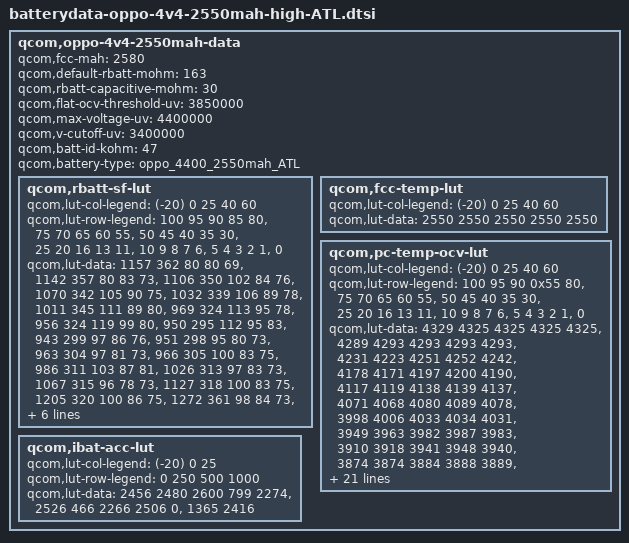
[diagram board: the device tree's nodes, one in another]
/* Copyright (c) 2020, The Linux Foundation. All rights reserved.
*  Copyright (c) 2020, the_shahnawaz_sheikh (sheikhshahnawaz41299).
*
* This program is free software; you can redistribute it and/or modify
* it under the terms of the GNU General Public License version 2 and
* only version 2 as published by the Free Software Foundation.
*
* This program is distributed in the hope that it will be useful,
* but WITHOUT ANY WARRANTY; without even the implied warranty of
* MERCHANTABILITY or FITNESS FOR A PARTICULAR PURPOSE.  See the
* GNU General Public License for more details.
*/

		qcom,oppo-4v4-2550mah-data {
			qcom,fcc-mah = <2580>;
			qcom,default-rbatt-mohm = <163>;
			qcom,rbatt-capacitive-mohm = <30>;
			qcom,flat-ocv-threshold-uv = <3850000>;
			qcom,max-voltage-uv = <4400000>;
			qcom,v-cutoff-uv = <3400000>;
			qcom,batt-id-kohm = <47>;
			qcom,battery-type = "oppo_4400_2550mah_ATL";

			qcom,rbatt-sf-lut {
				qcom,lut-col-legend = <(-20) 0 25 40 60>;
				qcom,lut-row-legend = <100 95 90 85 80>,
				                   <75 70 65 60 55>,
								   <50 45 40 35 30>,
								   <25 20 16 13 11>,
								   <10 9 8 7 6>,
								   <5 4 3 2 1>,
								   <0>;
				qcom,lut-data = <1157 362 80 80 69>,
				                 <1142 357 80 83 73>,
								 <1106 350 102 84 76>,
								 <1070 342 105 90 75>,
								 <1032 339 106 89 78>,
								 <1011 345 111 89 80>,
								 <969 324 113 95 78>,
								 <956 324 119 99 80>,
								 <950 295 112 95 83>,
								 <943 299 97 86 76>,
								 <951 298 95 80 73>,
								 <963 304 97 81 73>,
								 <966 305 100 83 75>,
								 <986 311 103 87 81>,
								 <1026 313 97 83 73>,
								 <1067 315 96 78 73>,
								 <1127 318 100 83 75>,
								 <1205 320 100 86 75>,
								 <1272 361 98 84 73>,
								 <1312 372 99 83 78>,
								 <1330 381 101 87 76>,
								 <1376 383 104 86 75>,
								 <1401 389 108 87 78>,
								 <1428 393 113 92 76>,
								 <1456 407 110 89 78>,
								 <1529 421 109 89 75>,
								 <1566 431 114 90 78>,
								 <1613 448 122 96 83>,
								 <1671 499 129 104 90>,
								 <1651 551 806 170 107>,
								 <4587 805 917 229 754>;
			};

			qcom,fcc-temp-lut {
				qcom,lut-col-legend = <(-20) 0 25 40 60>;
				qcom,lut-data = <2550 2550 2550 2550 2550>;
			};

			qcom,pc-temp-ocv-lut {
				qcom,lut-col-legend = <(-20) 0 25 40 60>;
				qcom,lut-row-legend = <100 95 90 0x55 80>,
				                       <75 70 65 60 55>,
									   <50 45 40 35 30>,
									   <25 20 16 13 11>,
									   <10 9 8 7 6>,
									   <5 4 3 2 1>,
									   <0>;
				qcom,lut-data = <4329 4325 4325 4325 4325>,
				                 <4289 4293 4293 4293 4293>,
								 <4231 4223 4251 4252 4242>,
								 <4178 4171 4197 4200 4190>,
								 <4117 4119 4138 4139 4137>,
								 <4071 4068 4080 4089 4078>,
								 <3998 4006 4033 4034 4031>,
								 <3949 3963 3982 3987 3983>,
								 <3910 3918 3941 3948 3940>,
								 <3874 3874 3884 3888 3889>,
								 <3846 3847 3856 3860 3855>,
								 <3824 3821 3829 3833 3832>,
								 <3805 3806 3813 3813 3809>,
								 <3792 3790 3796 3797 3795>,
								 <3783 3774 3779 3781 3778>,
								 <3773 3759 3762 3754 3744>,
								 <3759 3741 3743 3739 3725>,
								 <3743 3721 3722 3719 3705>,
								 <3727 3702 3702 3699 3687>,
								 <3718 3700 3697 3689 3678>,
								 <3713 3698 3694 3689 3679>,
								 <3707 3697 3693 3689 3677>,
								 <3703 3696 3694 3687 3675>,
								 <3700 3691 3689 3684 3672>,
								 <3697 3689 3685 3681 3668>,
								 <3688 3678 3670 3670 3636>,
								 <3682 3656 3605 3612 3604>,
								 <3673 3621 3560 3572 3566>,
								 <3661 3524 3506 3524 3520>,
								 <3611 3453 3326 3372 3382>,
								 <3000 3000 3000 3000 3000>;
			};

			qcom,ibat-acc-lut {
				qcom,lut-col-legend = <(-20) 0 25>;
				qcom,lut-row-legend = <0 250 500 1000>;
				qcom,lut-data = <2456 2480 2600 799 2274>,
				                 <2526 466 2266 2506 0>,
								 <1365 2416>;
			};
		};
		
